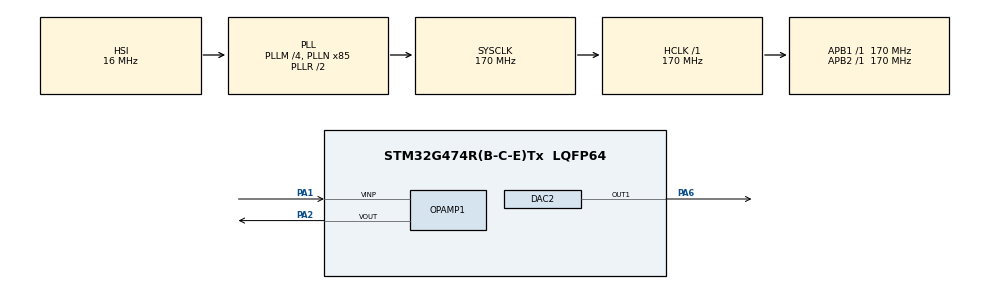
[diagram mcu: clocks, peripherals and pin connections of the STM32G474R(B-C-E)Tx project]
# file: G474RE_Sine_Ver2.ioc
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Mcu.Family=STM32G4
Mcu.Name=STM32G474R(B-C-E)Tx
Mcu.Package=LQFP64
NVIC.PriorityGroup=NVIC_PRIORITYGROUP_4
NVIC.TIM2_IRQn=true\:0\:0\:false\:false\:true\:true\:true\:true
PA1.Mode=Follower
PA1.Signal=OPAMP1_VINP
PA13.Mode=Serial_Wire
PA13.Signal=SYS_JTMS-SWDIO
PA14.Mode=Serial_Wire
PA14.Signal=SYS_JTCK-SWCLK
PA2.Mode=Follower
PA2.Signal=OPAMP1_VOUT
PA6.Signal=COMP_DAC21_group
PC14-OSC32_IN.Mode=LSE-External-Oscillator
PC14-OSC32_IN.Signal=RCC_OSC32_IN
PC15-OSC32_OUT.Mode=LSE-External-Oscillator
PC15-OSC32_OUT.Signal=RCC_OSC32_OUT
PF0-OSC_IN.Mode=HSE-External-Oscillator
PF0-OSC_IN.Signal=RCC_OSC_IN
PF1-OSC_OUT.Mode=HSE-External-Oscillator
PF1-OSC_OUT.Signal=RCC_OSC_OUT
ProjectManager.HeapSize=0x200
ProjectManager.StackSize=0x400
ProjectManager.TargetToolchain=STM32CubeIDE
RCC.ADC12Freq_Value=170000000
RCC.ADC345Freq_Value=170000000
RCC.AHBFreq_Value=170000000
RCC.APB1Freq_Value=170000000
RCC.APB1TimFreq_Value=170000000
RCC.APB2Freq_Value=170000000
RCC.APB2TimFreq_Value=170000000
RCC.CortexFreq_Value=170000000
RCC.EXTERNAL_CLOCK_VALUE=12288000
RCC.HCLKFreq_Value=170000000
RCC.HSE_VALUE=8000000
RCC.HSI48_VALUE=48000000
RCC.HSI_VALUE=16000000
RCC.PLLM=RCC_PLLM_DIV4
RCC.PLLN=85
RCC.SYSCLKFreq_VALUE=170000000
RCC.SYSCLKSource=RCC_SYSCLKSOURCE_PLLCLK
RCC.USBFreq_Value=170000000
RCC.VCOOutputFreq_Value=340000000
SH.COMP_DAC21_group.0=DAC2_OUT1,DAC_OUT1_ExtAndInt
TIM2.PeriodNoDither=105
TIM2.Prescaler=15
TIM2.TIM_MasterOutputTrigger=TIM_TRGO_UPDATE
VP_SYS_VS_DBSignals.Mode=DisableDeadBatterySignals
VP_TIM2_VS_ClockSourceINT.Mode=Internal
board=custom

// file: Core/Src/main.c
/* USER CODE BEGIN Header */
/**
 ******************************************************************************
 * @file           : main.c
 * @brief          : Main program body
 ******************************************************************************
 * @attention
 *
 * Copyright (c) 2025 STMicroelectronics.
 * All rights reserved.
 *
 * This software is licensed under terms that can be found in the LICENSE file
 * in the root directory of this software component.
 * If no LICENSE file comes with this software, it is provided AS-IS.
 *
 ******************************************************************************
 */
/* USER CODE END Header */
#include "main.h"

/* USER CODE BEGIN Includes */
#include <math.h>
/* USER CODE END Includes */

/* USER CODE BEGIN PTD */
#define SAMPLES 100
#define DAC_MAX 4095
/* USER CODE END PTD */

/* USER CODE BEGIN PD */
uint16_t sine_table[SAMPLES];
volatile uint16_t idx = 0;
/* USER CODE END PD */

DAC_HandleTypeDef hdac2;

OPAMP_HandleTypeDef hopamp1;

TIM_HandleTypeDef htim2;

void SystemClock_Config(void);
static void MX_GPIO_Init(void);
static void MX_DAC2_Init(void);
static void MX_TIM2_Init(void);
static void MX_OPAMP1_Init(void);

/* USER CODE BEGIN 0 */
void SineTable_Init(void) {
	for (int i = 0; i < SAMPLES; i++) {
		double theta = (2 * M_PI * i) / SAMPLES;
		sine_table[i] = (uint16_t) ((sin(theta) + 1.0) * (DAC_MAX / 2));
	}
}

void HAL_TIM_PeriodElapsedCallback(TIM_HandleTypeDef *htim) {
	if (htim->Instance == TIM2) {
		HAL_DAC_SetValue(&hdac2, DAC_CHANNEL_1, DAC_ALIGN_12B_R,
				sine_table[idx]);
		idx++;
		if (idx >= SAMPLES)
			idx = 0;
	}
}
/* USER CODE END 0 */

int main(void)
{

  /* MCU Configuration--------------------------------------------------------*/

  /* Reset of all peripherals, Initializes the Flash interface and the Systick. */
  HAL_Init();

  /* Configure the system clock */
  SystemClock_Config();

  /* Initialize all configured peripherals */
  MX_GPIO_Init();
  MX_DAC2_Init();
  MX_TIM2_Init();
  MX_OPAMP1_Init();
  /* USER CODE BEGIN 2 */
	SineTable_Init();

	HAL_DAC_Start(&hdac2, DAC_CHANNEL_1);
	HAL_TIM_Base_Start_IT(&htim2);
  /* USER CODE END 2 */

  /* Infinite loop */
	while (1) {

	}
}

void SystemClock_Config(void)
{
  RCC_OscInitTypeDef RCC_OscInitStruct = {0};
  RCC_ClkInitTypeDef RCC_ClkInitStruct = {0};

  /** Configure the main internal regulator output voltage
  */
  HAL_PWREx_ControlVoltageScaling(PWR_REGULATOR_VOLTAGE_SCALE1_BOOST);

  /** Initializes the RCC Oscillators according to the specified parameters
  * in the RCC_OscInitTypeDef structure.
  */
  RCC_OscInitStruct.OscillatorType = RCC_OSCILLATORTYPE_HSI;
  RCC_OscInitStruct.HSIState = RCC_HSI_ON;
  RCC_OscInitStruct.HSICalibrationValue = RCC_HSICALIBRATION_DEFAULT;
  RCC_OscInitStruct.PLL.PLLState = RCC_PLL_ON;
  RCC_OscInitStruct.PLL.PLLSource = RCC_PLLSOURCE_HSI;
  RCC_OscInitStruct.PLL.PLLM = RCC_PLLM_DIV4;
  RCC_OscInitStruct.PLL.PLLN = 85;
  RCC_OscInitStruct.PLL.PLLP = RCC_PLLP_DIV2;
  RCC_OscInitStruct.PLL.PLLQ = RCC_PLLQ_DIV2;
  RCC_OscInitStruct.PLL.PLLR = RCC_PLLR_DIV2;
  if (HAL_RCC_OscConfig(&RCC_OscInitStruct) != HAL_OK)
  {
    Error_Handler();
  }

  /** Initializes the CPU, AHB and APB buses clocks
  */
  RCC_ClkInitStruct.ClockType = RCC_CLOCKTYPE_HCLK|RCC_CLOCKTYPE_SYSCLK
                              |RCC_CLOCKTYPE_PCLK1|RCC_CLOCKTYPE_PCLK2;
  RCC_ClkInitStruct.SYSCLKSource = RCC_SYSCLKSOURCE_PLLCLK;
  RCC_ClkInitStruct.AHBCLKDivider = RCC_SYSCLK_DIV1;
  RCC_ClkInitStruct.APB1CLKDivider = RCC_HCLK_DIV1;
  RCC_ClkInitStruct.APB2CLKDivider = RCC_HCLK_DIV1;

  if (HAL_RCC_ClockConfig(&RCC_ClkInitStruct, FLASH_LATENCY_4) != HAL_OK)
  {
    Error_Handler();
  }
}

static void MX_DAC2_Init(void)
{

  DAC_ChannelConfTypeDef sConfig = {0};

  /** DAC Initialization
  */
  hdac2.Instance = DAC2;
  if (HAL_DAC_Init(&hdac2) != HAL_OK)
  {
    Error_Handler();
  }

  /** DAC channel OUT1 config
  */
  sConfig.DAC_HighFrequency = DAC_HIGH_FREQUENCY_INTERFACE_MODE_AUTOMATIC;
  sConfig.DAC_DMADoubleDataMode = DISABLE;
  sConfig.DAC_SignedFormat = DISABLE;
  sConfig.DAC_SampleAndHold = DAC_SAMPLEANDHOLD_DISABLE;
  sConfig.DAC_Trigger = DAC_TRIGGER_NONE;
  sConfig.DAC_Trigger2 = DAC_TRIGGER_NONE;
  sConfig.DAC_OutputBuffer = DAC_OUTPUTBUFFER_ENABLE;
  sConfig.DAC_ConnectOnChipPeripheral = DAC_CHIPCONNECT_BOTH;
  sConfig.DAC_UserTrimming = DAC_TRIMMING_FACTORY;
  if (HAL_DAC_ConfigChannel(&hdac2, &sConfig, DAC_CHANNEL_1) != HAL_OK)
  {
    Error_Handler();
  }

}

static void MX_OPAMP1_Init(void)
{

  hopamp1.Instance = OPAMP1;
  hopamp1.Init.PowerMode = OPAMP_POWERMODE_NORMALSPEED;
  hopamp1.Init.Mode = OPAMP_FOLLOWER_MODE;
  hopamp1.Init.NonInvertingInput = OPAMP_NONINVERTINGINPUT_IO0;
  hopamp1.Init.InternalOutput = DISABLE;
  hopamp1.Init.TimerControlledMuxmode = OPAMP_TIMERCONTROLLEDMUXMODE_DISABLE;
  hopamp1.Init.UserTrimming = OPAMP_TRIMMING_FACTORY;
  if (HAL_OPAMP_Init(&hopamp1) != HAL_OK)
  {
    Error_Handler();
  }

}

static void MX_TIM2_Init(void)
{

  TIM_ClockConfigTypeDef sClockSourceConfig = {0};
  TIM_MasterConfigTypeDef sMasterConfig = {0};

  htim2.Instance = TIM2;
  htim2.Init.Prescaler = 15;
  htim2.Init.CounterMode = TIM_COUNTERMODE_UP;
  htim2.Init.Period = 105;
  htim2.Init.ClockDivision = TIM_CLOCKDIVISION_DIV1;
  htim2.Init.AutoReloadPreload = TIM_AUTORELOAD_PRELOAD_DISABLE;
  if (HAL_TIM_Base_Init(&htim2) != HAL_OK)
  {
    Error_Handler();
  }
  sClockSourceConfig.ClockSource = TIM_CLOCKSOURCE_INTERNAL;
  if (HAL_TIM_ConfigClockSource(&htim2, &sClockSourceConfig) != HAL_OK)
  {
    Error_Handler();
  }
  sMasterConfig.MasterOutputTrigger = TIM_TRGO_UPDATE;
  sMasterConfig.MasterSlaveMode = TIM_MASTERSLAVEMODE_DISABLE;
  if (HAL_TIMEx_MasterConfigSynchronization(&htim2, &sMasterConfig) != HAL_OK)
  {
    Error_Handler();
  }

}

static void MX_GPIO_Init(void)
{

  /* GPIO Ports Clock Enable */
  __HAL_RCC_GPIOC_CLK_ENABLE();
  __HAL_RCC_GPIOF_CLK_ENABLE();
  __HAL_RCC_GPIOA_CLK_ENABLE();

}

void Error_Handler(void)
{
	__disable_irq();
	while (1) {
	}
}
